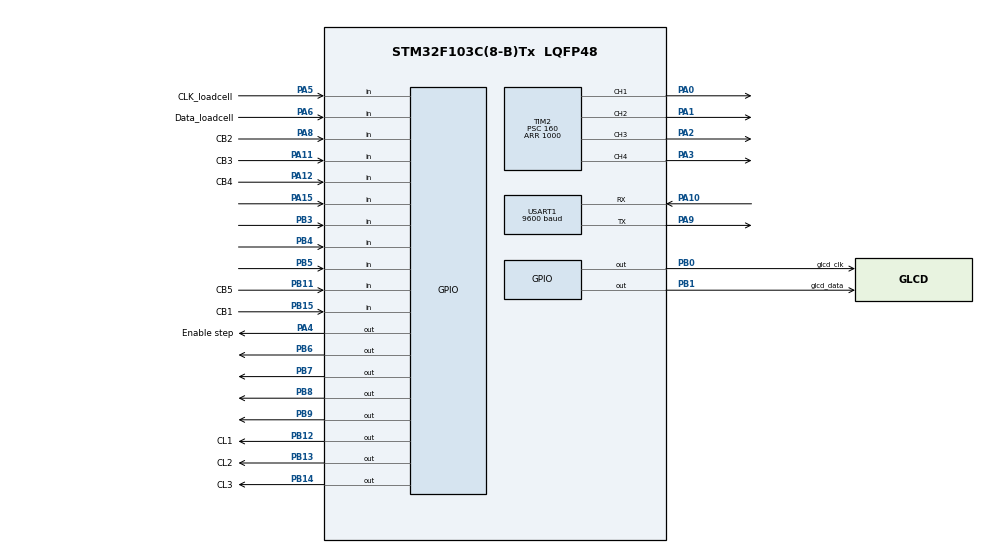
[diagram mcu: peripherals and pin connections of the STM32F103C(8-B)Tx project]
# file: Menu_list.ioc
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Mcu.Family=STM32F1
Mcu.Name=STM32F103C(8-B)Tx
Mcu.Package=LQFP48
NVIC.PriorityGroup=NVIC_PRIORITYGROUP_4
NVIC.TIM2_IRQn=true\:0\:0\:false\:false\:true\:true\:true
NVIC.USART1_IRQn=true\:0\:0\:false\:false\:true\:true\:true
PA0-WKUP.Signal=S_TIM2_CH1_ETR
PA1.Signal=S_TIM2_CH2
PA10.Mode=Asynchronous
PA10.Signal=USART1_RX
PA11.GPIO_Label=CB3
PA11.GPIO_PuPd=GPIO_PULLUP
PA11.Signal=GPIO_Input
PA12.GPIO_Label=CB4
PA12.GPIO_PuPd=GPIO_PULLUP
PA12.Signal=GPIO_Input
PA13.Mode=Serial_Wire
PA13.Signal=SYS_JTMS-SWDIO
PA14.Mode=Serial_Wire
PA14.Signal=SYS_JTCK-SWCLK
PA15.GPIO_PuPd=GPIO_PULLUP
PA15.Signal=GPIO_Input
PA2.Signal=S_TIM2_CH3
PA3.Signal=S_TIM2_CH4
PA4.GPIO_Label=Enable step
PA4.Signal=GPIO_Output
PA5.GPIO_Label=CLK_loadcell
PA5.Signal=GPIO_Input
PA6.GPIO_Label=Data_loadcell
PA6.Signal=GPIO_Input
PA8.GPIO_Label=CB2
PA8.GPIO_PuPd=GPIO_PULLUP
PA8.Signal=GPIO_Input
PA9.Mode=Asynchronous
PA9.Signal=USART1_TX
PB0.GPIO_Label=glcd_clk
PB0.GPIO_Speed=GPIO_SPEED_FREQ_LOW
PB0.Signal=GPIO_Output
PB1.GPIO_Label=glcd_data
PB1.Signal=GPIO_Output
PB11.GPIO_Label=CB5
PB11.GPIO_PuPd=GPIO_PULLUP
PB11.Signal=GPIO_Input
PB12.GPIO_Label=CL1
PB12.Signal=GPIO_Output
PB13.GPIO_Label=CL2
PB13.Signal=GPIO_Output
PB14.GPIO_Label=CL3
PB14.Signal=GPIO_Output
PB15.GPIO_Label=CB1
PB15.GPIO_PuPd=GPIO_PULLUP
PB15.Signal=GPIO_Input
PB3.GPIO_PuPd=GPIO_PULLUP
PB3.Signal=GPIO_Input
PB4.GPIO_PuPd=GPIO_PULLUP
PB4.Signal=GPIO_Input
PB5.GPIO_PuPd=GPIO_PULLUP
PB5.Signal=GPIO_Input
PB6.Signal=GPIO_Output
PB7.Signal=GPIO_Output
PB8.Signal=GPIO_Output
PB9.Signal=GPIO_Output
PC14-OSC32_IN.Mode=LSE-External-Oscillator
PC14-OSC32_IN.Signal=RCC_OSC32_IN
PC15-OSC32_OUT.Mode=LSE-External-Oscillator
PC15-OSC32_OUT.Signal=RCC_OSC32_OUT
PD0-OSC_IN.Mode=HSE-External-Oscillator
PD0-OSC_IN.Signal=RCC_OSC_IN
PD1-OSC_OUT.Mode=HSE-External-Oscillator
PD1-OSC_OUT.Signal=RCC_OSC_OUT
ProjectManager.HeapSize=0x200
ProjectManager.StackSize=0x400
ProjectManager.TargetToolchain=MDK-ARM V5
RCC.APB1Freq_Value=8000000
RCC.APB2Freq_Value=8000000
SH.S_TIM2_CH1_ETR.0=TIM2_CH1,PWM Generation1 CH1
SH.S_TIM2_CH2.0=TIM2_CH2,PWM Generation2 CH2
SH.S_TIM2_CH3.0=TIM2_CH3,PWM Generation3 CH3
SH.S_TIM2_CH4.0=TIM2_CH4,PWM Generation4 CH4
TIM2.AutoReloadPreload=TIM_AUTORELOAD_PRELOAD_ENABLE
TIM2.Channel-PWM\ Generation1\ CH1=TIM_CHANNEL_1
TIM2.Channel-PWM\ Generation2\ CH2=TIM_CHANNEL_2
TIM2.Channel-PWM\ Generation3\ CH3=TIM_CHANNEL_3
TIM2.Channel-PWM\ Generation4\ CH4=TIM_CHANNEL_4
TIM2.Period=1000
TIM2.Prescaler=160
USART1.BaudRate=9600
USART1.VirtualMode=VM_ASYNC
board=custom

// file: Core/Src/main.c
/* USER CODE BEGIN Header */
/**
  ******************************************************************************
  * @file           : main.c
  * @brief          : Main program body
  ******************************************************************************
  * @attention
  *
  * <h2><center>&copy; Copyright (c) 2021 STMicroelectronics.
  * All rights reserved.</center></h2>
  *
  * This software component is licensed by ST under BSD 3-Clause license,
  * the "License"; You may not use this file except in compliance with the
  * License. You may obtain a copy of the License at:
  *                        opensource.org/licenses/BSD-3-Clause
  *
  ******************************************************************************
  */
/* USER CODE END Header */
#include "main.h"
#include "tim.h"
#include "usart.h"
#include "gpio.h"

/* USER CODE BEGIN Includes */
#include "glcd.h"
#include "com.h"
/* USER CODE END Includes */

/* USER CODE BEGIN PV */
extern const unsigned char logo[];
extern uint8_t u8g_RxBuff;
/* USER CODE END PV */

void SystemClock_Config(void);

int main(void)
{

  /* MCU Configuration--------------------------------------------------------*/

  /* Reset of all peripherals, Initializes the Flash interface and the Systick. */
  HAL_Init();

  /* Configure the system clock */
  SystemClock_Config();

  /* Initialize all configured peripherals */
  MX_GPIO_Init();
  MX_TIM2_Init();
  MX_USART1_UART_Init();
  /* USER CODE BEGIN 2 */
	HAL_Delay(15000u);
	COM_TestReceiveFromEsp();
  /* USER CODE END 2 */

  /* Infinite loop */
  while (1)
  {

    /* USER CODE BEGIN 3 */
		COM_TestCmdToEsp();
  }
  /* USER CODE END 3 */
}

void SystemClock_Config(void)
{
  RCC_OscInitTypeDef RCC_OscInitStruct = {0};
  RCC_ClkInitTypeDef RCC_ClkInitStruct = {0};

  /** Initializes the RCC Oscillators according to the specified parameters
  * in the RCC_OscInitTypeDef structure.
  */
  RCC_OscInitStruct.OscillatorType = RCC_OSCILLATORTYPE_HSI;
  RCC_OscInitStruct.HSIState = RCC_HSI_ON;
  RCC_OscInitStruct.HSICalibrationValue = RCC_HSICALIBRATION_DEFAULT;
  RCC_OscInitStruct.PLL.PLLState = RCC_PLL_NONE;
  if (HAL_RCC_OscConfig(&RCC_OscInitStruct) != HAL_OK)
  {
    Error_Handler();
  }
  /** Initializes the CPU, AHB and APB buses clocks
  */
  RCC_ClkInitStruct.ClockType = RCC_CLOCKTYPE_HCLK|RCC_CLOCKTYPE_SYSCLK
                              |RCC_CLOCKTYPE_PCLK1|RCC_CLOCKTYPE_PCLK2;
  RCC_ClkInitStruct.SYSCLKSource = RCC_SYSCLKSOURCE_HSI;
  RCC_ClkInitStruct.AHBCLKDivider = RCC_SYSCLK_DIV1;
  RCC_ClkInitStruct.APB1CLKDivider = RCC_HCLK_DIV1;
  RCC_ClkInitStruct.APB2CLKDivider = RCC_HCLK_DIV1;

  if (HAL_RCC_ClockConfig(&RCC_ClkInitStruct, FLASH_LATENCY_0) != HAL_OK)
  {
    Error_Handler();
  }
}

void Error_Handler(void)
{
  __disable_irq();
  while (1)
  {
  }
}

/************************ (C) COPYRIGHT STMicroelectronics *****END OF FILE****/
